# M367 register map
File version: 0.1
CPU: 
Registers are 32-bit, read-write, reset 0x0 unless marked. A register's access mark holds for its fields unless they carry their own. Offsets are from the block's base; [hi:lo] are bit positions; {n}, {i} and the like mark numbered series.

## DA0 — Digital-to-Analog Converter (DA)
Base 0x40054000
Same registers: DA1 0x40055000
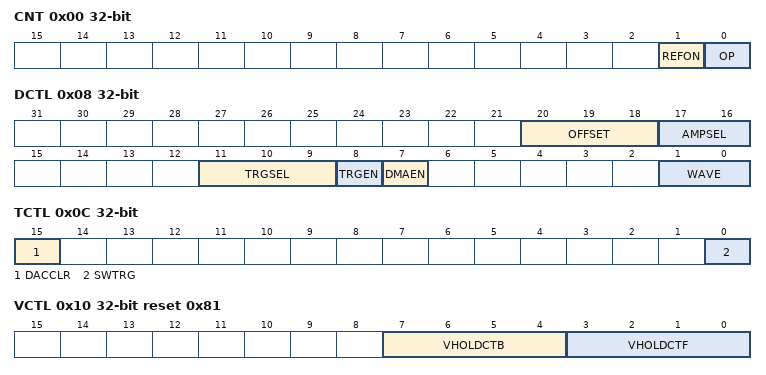
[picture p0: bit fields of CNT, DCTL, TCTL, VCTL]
0x00 CNT — DAC Control Register1
  [1] REFON, [0] OP
0x04 REG — DAC Data Register
  [15:6] DAC
0x08 DCTL — DAC Output Register
  [20:18] OFFSET, [17:16] AMPSEL, [11:9] TRGSEL, [8] TRGEN, [7] DMAEN, [1:0] WAVE
0x0C TCTL wo — DAC Trigger Register
  [15] DACCLR, [0] SWTRG
0x10 VCTL reset 0x81 — DAC Control Register2
  [7:4] VHOLDCTB, [3:0] VHOLDCTF

## EXB — External Bus Interface(EXB)
Base 0x4005C000
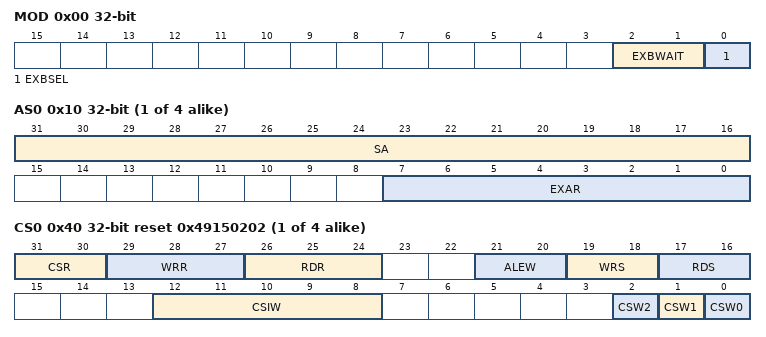
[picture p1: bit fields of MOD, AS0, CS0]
0x00 MOD — External Bus Mode Register
  [2:1] EXBWAIT, [0] EXBSEL
{0x10+4i} AS{i} (i=0..3) — External Bus Base Address and CS Space setting Register {i}
  [31:16] SA, [7:0] EXAR
{0x40+4i} CS{i} reset 0x49150202 (i=0..3) — Chip Select and Wait Controller Register {i}
  [31:30] CSR, [29:27] WRR, [26:24] RDR, [21:20] ALEW, [19:18] WRS, [17:16] RDS, [12:8] CSIW, [2] CSW2, [1] CSW1, [0] CSW0

## PA — General Purpose Input_Output Port (PA)
Base 0x400C0000
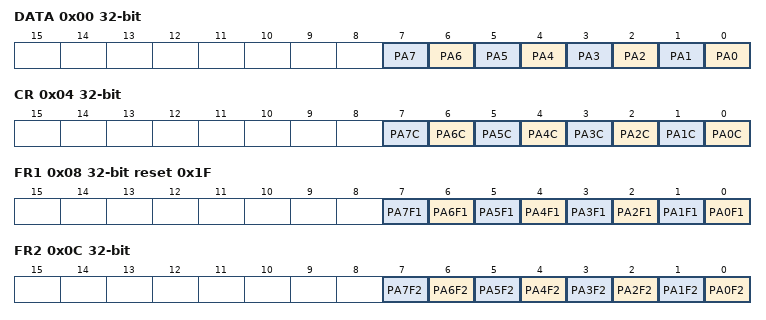
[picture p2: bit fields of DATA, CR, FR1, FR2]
0x00 DATA — PA Data Register
  [n] PA{n} (n=0..7)
0x04 CR — PA Control Register
  [n] PA{n}C (n=0..7)
0x08 FR1 reset 0x1F — PA Function Register 1
  [n] PA{n}F1 (n=0..7)
0x0C FR2 — PA Function Register 2
  [n] PA{n}F2 (n=0..7)
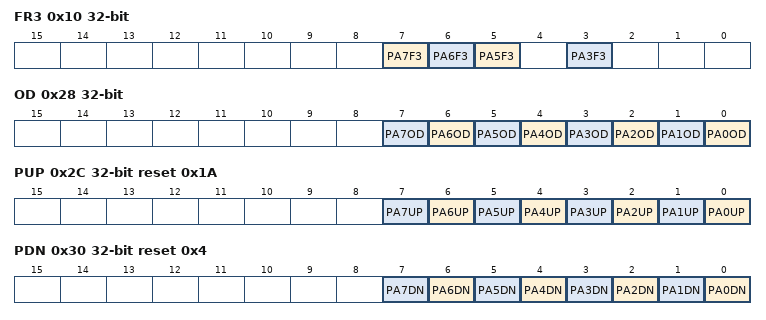
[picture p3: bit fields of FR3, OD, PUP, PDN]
0x10 FR3 — PA Function Register 3
  [7] PA7F3, [6] PA6F3, [5] PA5F3, [3] PA3F3
0x14 FR4 — PA Function Register 4
  [7] PA7F4
0x18 FR5 — PA Function Register 5
  [7] PA7F5
0x28 OD — PA Open Drain Control Register
  [n] PA{n}OD (n=0..7)
0x2C PUP reset 0x1A — PA Pull-Up Control Register
  [n] PA{n}UP (n=0..7)
0x30 PDN reset 0x4 — PA Pull-Down Control Register
  [n] PA{n}DN (n=0..7)
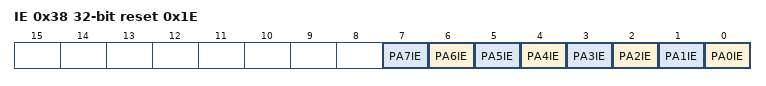
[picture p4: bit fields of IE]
0x38 IE reset 0x1E — PA Input Enable Control Register
  [n] PA{n}IE (n=0..7)

## PB — General Purpose Input_Output Port (PB)
Base 0x400C0100
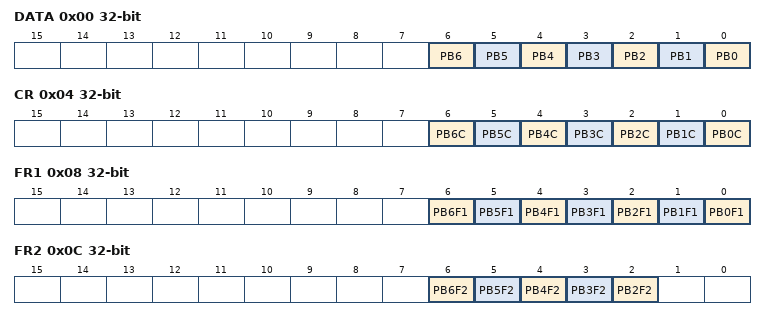
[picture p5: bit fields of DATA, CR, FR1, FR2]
0x00 DATA — PB Data Register
  [n] PB{n} (n=0..6)
0x04 CR — PB Control Register
  [n] PB{n}C (n=0..6)
0x08 FR1 — PB Function Register 1
  [n] PB{n}F1 (n=0..6)
0x0C FR2 — PB Function Register 2
  [n] PB{n}F2 (n=2..6)
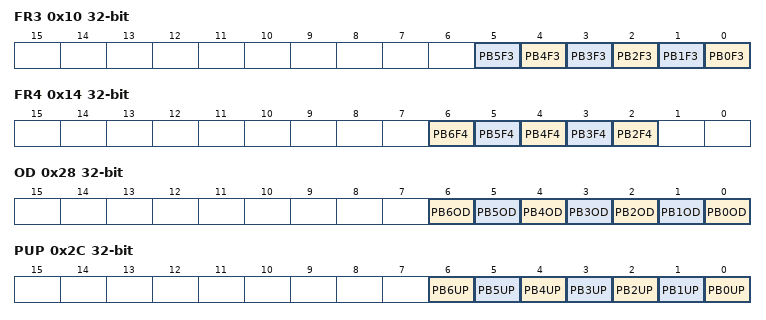
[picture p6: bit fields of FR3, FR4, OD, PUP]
0x10 FR3 — PB Function Register 3
  [n] PB{n}F3 (n=0..5)
0x14 FR4 — PB Function Register 4
  [n] PB{n}F4 (n=2..6)
0x28 OD — PB Open Drain Control Register
  [n] PB{n}OD (n=0..6)
0x2C PUP — PB Pull-Up Control Register
  [n] PB{n}UP (n=0..6)
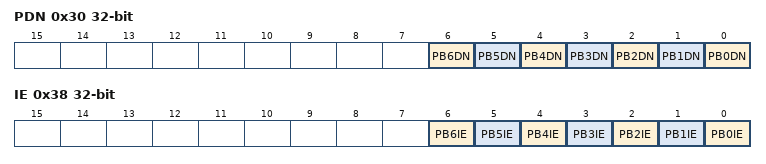
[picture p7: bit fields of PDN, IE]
0x30 PDN — PB Pull-Down Control Register
  [n] PB{n}DN (n=0..6)
0x38 IE — PB Input Enable Control Register
  [n] PB{n}IE (n=0..6)

## PE — General Purpose Input_Output Port (PE)
Base 0x400C0400
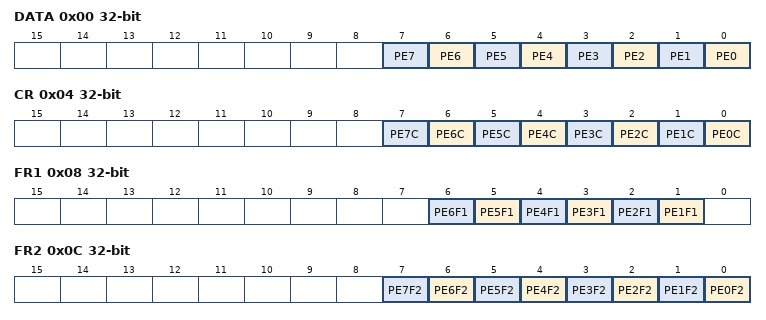
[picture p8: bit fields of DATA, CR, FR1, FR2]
0x00 DATA — PE Data Register
  [n] PE{n} (n=0..7)
0x04 CR — PE Control Register
  [n] PE{n}C (n=0..7)
0x08 FR1 — PE Function Register 1
  [n] PE{n}F1 (n=1..6)
0x0C FR2 — PE Function Register 2
  [n] PE{n}F2 (n=0..7)
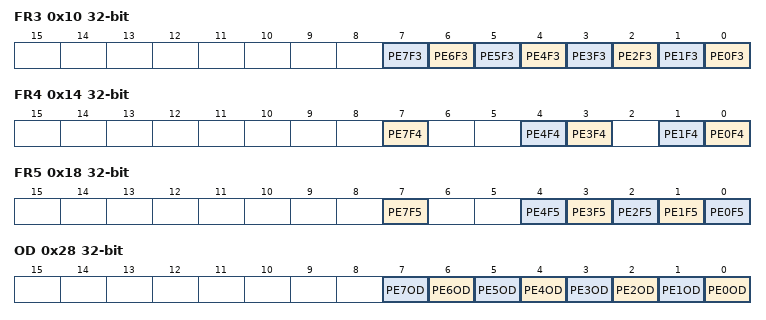
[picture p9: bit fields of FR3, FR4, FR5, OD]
0x10 FR3 — PE Function Register 3
  [n] PE{n}F3 (n=0..7)
0x14 FR4 — PE Function Register 4
  [7] PE7F4, [4] PE4F4, [3] PE3F4, [1] PE1F4, [0] PE0F4
0x18 FR5 — PE Function Register 5
  [7] PE7F5, [n] PE{n}F5 (n=0..4)
0x28 OD — PE Open Drain Control Register
  [n] PE{n}OD (n=0..7)
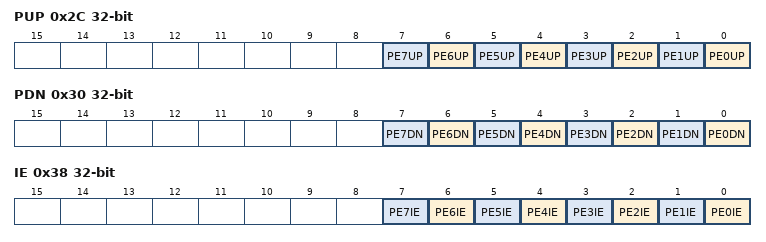
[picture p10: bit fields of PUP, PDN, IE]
0x2C PUP — PE Pull-Up Control Register
  [n] PE{n}UP (n=0..7)
0x30 PDN — PE Pull-Down Control Register
  [n] PE{n}DN (n=0..7)
0x38 IE — PE Input Enable Control Register
  [n] PE{n}IE (n=0..7)

## PF — General Purpose Input_Output Port (PF)
Base 0x400C0500
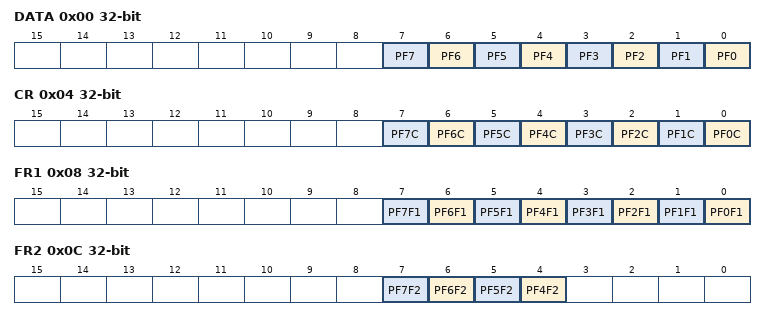
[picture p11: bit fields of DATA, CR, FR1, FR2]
0x00 DATA — PF Data Register
  [n] PF{n} (n=0..7)
0x04 CR — PF Control Register
  [n] PF{n}C (n=0..7)
0x08 FR1 — PF Function Register 1
  [n] PF{n}F1 (n=0..7)
0x0C FR2 — PF Function Register 2
  [n] PF{n}F2 (n=4..7)
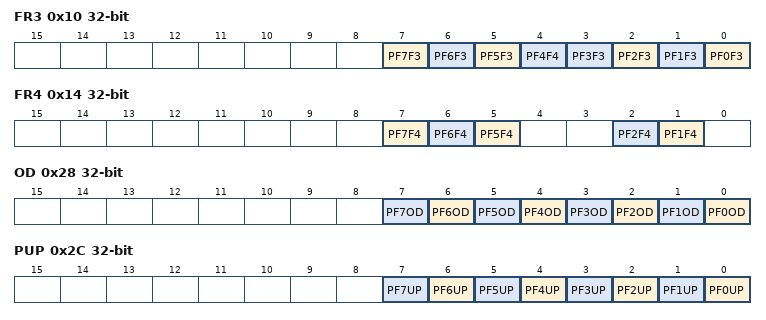
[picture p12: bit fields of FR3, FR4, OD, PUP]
0x10 FR3 — PF Function Register 3
  [7] PF7F3, [6] PF6F3, [5] PF5F3, [4] PF4F4, [n] PF{n}F3 (n=0..3)
0x14 FR4 — PF Function Register 4
  [7] PF7F4, [6] PF6F4, [5] PF5F4, [2] PF2F4, [1] PF1F4
0x28 OD — PF Open Drain Control Register
  [n] PF{n}OD (n=0..7)
0x2C PUP — PF Pull-Up Control Register
  [n] PF{n}UP (n=0..7)
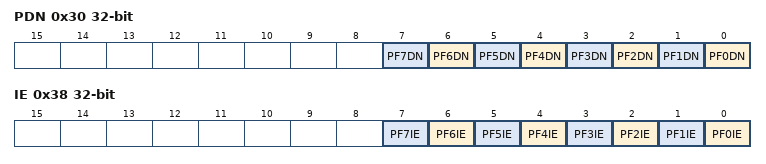
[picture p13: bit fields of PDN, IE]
0x30 PDN — PF Pull-Down Control Register
  [n] PF{n}DN (n=0..7)
0x38 IE — PF Input Enable Control Register
  [n] PF{n}IE (n=0..7)
